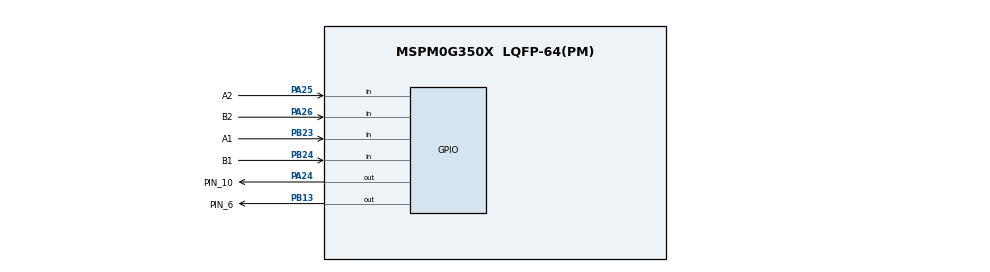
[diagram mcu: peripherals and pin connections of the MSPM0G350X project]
/**
 *
 * @cliArgs --device "MSPM0G350X" --part "Default" --package "LQFP-64(PM)" --product "mspm0_sdk@2.10.00.04"
 * @versions {"tool":"1.28.0+4712"}
 */

/**
 * Import the modules used in this configuration.
 */
const ADC12   = scripting.addModule("/ti/driverlib/ADC12", {}, false);
const ADC121  = ADC12.addInstance();
const GPIO    = scripting.addModule("/ti/driverlib/GPIO", {}, false);
const GPIO1   = GPIO.addInstance();
const GPIO2   = GPIO.addInstance();
const GPIO3   = GPIO.addInstance();
const GPIO4   = GPIO.addInstance();
const GPIO5   = GPIO.addInstance();
const GPIO6   = GPIO.addInstance();
const GPIO7   = GPIO.addInstance();
const GPIO8   = GPIO.addInstance();
const GPIO9   = GPIO.addInstance();
const GPIO10  = GPIO.addInstance();
const PWM     = scripting.addModule("/ti/driverlib/PWM", {}, false);
const PWM1    = PWM.addInstance();
const PWM2    = PWM.addInstance();
const SPI     = scripting.addModule("/ti/driverlib/SPI", {}, false);
const SPI1    = SPI.addInstance();
const SPI2    = SPI.addInstance();
const SYSCTL  = scripting.addModule("/ti/driverlib/SYSCTL");
const SYSTICK = scripting.addModule("/ti/driverlib/SYSTICK");
const TIMER   = scripting.addModule("/ti/driverlib/TIMER", {}, false);
const TIMER1  = TIMER.addInstance();
const TIMER2  = TIMER.addInstance();
const TIMER3  = TIMER.addInstance();
const UART    = scripting.addModule("/ti/driverlib/UART", {}, false);
const UART1   = UART.addInstance();
const UART2   = UART.addInstance();
const UART3   = UART.addInstance();
const UART4   = UART.addInstance();

/**
 * Write custom configuration values to the imported modules.
 */
const divider7       = system.clockTree["PLL_PDIV"];
divider7.divideValue = 2;

const divider9       = system.clockTree["UDIV"];
divider9.divideValue = 2;

const multiplier2         = system.clockTree["PLL_QDIV"];
multiplier2.multiplyValue = 5;

const mux8       = system.clockTree["HSCLKMUX"];
mux8.inputSelect = "HSCLKMUX_SYSPLL2X";

ADC121.$name                             = "ADCGraySensor";
ADC121.adcPin0Config.hideOutputInversion = scripting.forceWrite(false);
ADC121.adcPin0Config.$name               = "ti_driverlib_gpio_GPIOPinGeneric18";

const Board = scripting.addModule("/ti/driverlib/Board", {}, false);

GPIO1.$name                   = "GraySensor";
GPIO1.associatedPins.create(3);
GPIO1.associatedPins[0].$name = "PIN_0";
GPIO1.associatedPins[1].$name = "PIN_1";
GPIO1.associatedPins[2].$name = "PIN_2";

GPIO2.$name                   = "Key";
GPIO2.associatedPins.create(3);
GPIO2.associatedPins[0].$name = "PIN_3";
GPIO2.associatedPins[1].$name = "PIN_4";
GPIO2.associatedPins[2].$name = "PIN_5";

GPIO3.$name                         = "CS";
GPIO3.associatedPins[0].$name       = "PIN_6";
GPIO3.associatedPins[0].pin.$assign = "PB13";

GPIO4.$name                         = "Motor";
GPIO4.associatedPins.create(4);
GPIO4.associatedPins[0].$name       = "PIN_7";
GPIO4.associatedPins[1].$name       = "PIN_8";
GPIO4.associatedPins[2].$name       = "PIN_9";
GPIO4.associatedPins[3].$name       = "PIN_10";
GPIO4.associatedPins[3].pin.$assign = "PA24";

GPIO5.$name                               = "Encoder1";
GPIO5.associatedPins.create(2);
GPIO5.associatedPins[0].direction         = "INPUT";
GPIO5.associatedPins[0].$name             = "A1";
GPIO5.associatedPins[0].interruptEn       = true;
GPIO5.associatedPins[0].interruptPriority = "1";
GPIO5.associatedPins[0].polarity          = "RISE";
GPIO5.associatedPins[0].pin.$assign       = "PB23";
GPIO5.associatedPins[1].$name             = "B1";
GPIO5.associatedPins[1].direction         = "INPUT";
GPIO5.associatedPins[1].pin.$assign       = "PB24";

GPIO6.$name                   = "LED";
GPIO6.associatedPins[0].$name = "PIN_13";

GPIO7.$name                               = "Encoder2";
GPIO7.associatedPins.create(2);
GPIO7.associatedPins[0].$name             = "A2";
GPIO7.associatedPins[0].direction         = "INPUT";
GPIO7.associatedPins[0].interruptEn       = true;
GPIO7.associatedPins[0].interruptPriority = "1";
GPIO7.associatedPins[0].polarity          = "RISE";
GPIO7.associatedPins[0].pin.$assign       = "PA25";
GPIO7.associatedPins[1].$name             = "B2";
GPIO7.associatedPins[1].direction         = "INPUT";
GPIO7.associatedPins[1].pin.$assign       = "PA26";

GPIO8.$name                   = "DC";
GPIO8.associatedPins[0].$name = "PIN_11";

GPIO9.$name                   = "RES";
GPIO9.associatedPins[0].$name = "PIN_12";

GPIO10.$name                   = "BL";
GPIO10.associatedPins[0].$name = "PIN_14";

PWM1.$name               = "PWM_0";
PWM1.clockDivider        = 8;
PWM1.pwmMode             = "EDGE_ALIGN_UP";
PWM1.PWM_CHANNEL_0.$name = "ti_driverlib_pwm_PWMTimerCC0";
PWM1.PWM_CHANNEL_1.$name = "ti_driverlib_pwm_PWMTimerCC1";
PWM1.ccp0PinConfig.$name = "ti_driverlib_gpio_GPIOPinGeneric10";
PWM1.ccp1PinConfig.$name = "ti_driverlib_gpio_GPIOPinGeneric11";

PWM2.$name                              = "PWM_Buzzer";
PWM2.ccIndex                            = [0];
PWM2.clockDivider                       = 8;
PWM2.PWM_CHANNEL_0.$name                = "ti_driverlib_pwm_PWMTimerCC2";
PWM2.ccp0PinConfig.direction            = scripting.forceWrite("OUTPUT");
PWM2.ccp0PinConfig.hideOutputInversion  = scripting.forceWrite(false);
PWM2.ccp0PinConfig.onlyInternalResistor = scripting.forceWrite(false);
PWM2.ccp0PinConfig.passedPeripheralType = scripting.forceWrite("Digital");
PWM2.ccp0PinConfig.$name                = "ti_driverlib_gpio_GPIOPinGeneric19";

SPI1.$name               = "SPI_0";
SPI1.frameFormat         = "MOTO3";
SPI1.sclkPinConfig.$name = "ti_driverlib_gpio_GPIOPinGeneric14";
SPI1.mosiPinConfig.$name = "ti_driverlib_gpio_GPIOPinGeneric15";
SPI1.misoPinConfig.$name = "ti_driverlib_gpio_GPIOPinGeneric16";

SPI2.$name               = "SPI_1";
SPI2.sclkPinConfig.$name = "ti_driverlib_gpio_GPIOPinGeneric8";
SPI2.mosiPinConfig.$name = "ti_driverlib_gpio_GPIOPinGeneric9";
SPI2.misoPinConfig.$name = "ti_driverlib_gpio_GPIOPinGeneric12";
SPI2.cs0PinConfig.$name  = "ti_driverlib_gpio_GPIOPinGeneric13";

SYSCTL.forceDefaultClkConfig = true;
SYSCTL.clockTreeEn           = true;

SYSTICK.periodEnable      = true;
SYSTICK.interruptEnable   = true;
SYSTICK.systickEnable     = true;
SYSTICK.interruptPriority = "0";
SYSTICK.period            = 80000;

TIMER1.$name            = "TIMER_0";
TIMER1.timerMode        = "PERIODIC_UP";
TIMER1.timerPeriod      = "10 ms";
TIMER1.timerClkDiv      = 8;
TIMER1.interrupts       = ["ZERO"];
TIMER1.timerClkPrescale = 2;
TIMER1.timerStartTimer  = true;

TIMER2.$name            = "TIMER_1";
TIMER2.timerMode        = "PERIODIC";
TIMER2.timerPeriod      = "20 ms";
TIMER2.timerClkPrescale = 10;
TIMER2.timerClkDiv      = 8;

TIMER3.$name            = "TIMER_2";
TIMER3.timerMode        = "PERIODIC";
TIMER3.timerPeriod      = "50 ms";
TIMER3.timerClkDiv      = 8;
TIMER3.timerClkPrescale = 10;

UART1.$name             = "UART_0";
UART1.targetBaudRate    = 115200;
UART1.enabledInterrupts = ["RX"];
UART1.txPinConfig.$name = "ti_driverlib_gpio_GPIOPinGeneric0";
UART1.rxPinConfig.$name = "ti_driverlib_gpio_GPIOPinGeneric1";

UART2.$name             = "UART_1";
UART2.targetBaudRate    = 115200;
UART2.enabledInterrupts = ["RX"];
UART2.txPinConfig.$name = "ti_driverlib_gpio_GPIOPinGeneric2";
UART2.rxPinConfig.$name = "ti_driverlib_gpio_GPIOPinGeneric3";

UART3.$name             = "UART_2";
UART3.targetBaudRate    = 115200;
UART3.txPinConfig.$name = "ti_driverlib_gpio_GPIOPinGeneric4";
UART3.rxPinConfig.$name = "ti_driverlib_gpio_GPIOPinGeneric5";

UART4.$name             = "UART_3";
UART4.targetBaudRate    = 115200;
UART4.txPinConfig.$name = "ti_driverlib_gpio_GPIOPinGeneric6";
UART4.rxPinConfig.$name = "ti_driverlib_gpio_GPIOPinGeneric7";

/**
 * Pinmux solution for unlocked pins/peripherals. This ensures that minor changes to the automatic solver in a future
 * version of the tool will not impact the pinmux you originally saw.  These lines can be completely deleted in order to
 * re-solve from scratch.
 */
ADC121.peripheral.$suggestSolution            = "ADC1";
ADC121.peripheral.adcPin0.$suggestSolution    = "PA15";
Board.peripheral.$suggestSolution             = "DEBUGSS";
Board.peripheral.swclkPin.$suggestSolution    = "PA20";
Board.peripheral.swdioPin.$suggestSolution    = "PA19";
GPIO1.associatedPins[0].pin.$suggestSolution  = "PB19";
GPIO1.associatedPins[1].pin.$suggestSolution  = "PB20";
GPIO1.associatedPins[2].pin.$suggestSolution  = "PB21";
GPIO2.associatedPins[0].pin.$suggestSolution  = "PB22";
GPIO2.associatedPins[1].pin.$suggestSolution  = "PB25";
GPIO2.associatedPins[2].pin.$suggestSolution  = "PB26";
GPIO4.associatedPins[0].pin.$suggestSolution  = "PB27";
GPIO4.associatedPins[1].pin.$suggestSolution  = "PA28";
GPIO4.associatedPins[2].pin.$suggestSolution  = "PA30";
GPIO6.associatedPins[0].pin.$suggestSolution  = "PB14";
GPIO8.associatedPins[0].pin.$suggestSolution  = "PA12";
GPIO9.associatedPins[0].pin.$suggestSolution  = "PB17";
GPIO10.associatedPins[0].pin.$suggestSolution = "PB18";
PWM1.peripheral.$suggestSolution              = "TIMG7";
PWM1.peripheral.ccp0Pin.$suggestSolution      = "PA23";
PWM1.peripheral.ccp1Pin.$suggestSolution      = "PA27";
PWM2.peripheral.$suggestSolution              = "TIMG6";
PWM2.peripheral.ccp0Pin.$suggestSolution      = "PA29";
SPI1.peripheral.$suggestSolution              = "SPI1";
SPI1.peripheral.sclkPin.$suggestSolution      = "PB16";
SPI1.peripheral.mosiPin.$suggestSolution      = "PB15";
SPI1.peripheral.misoPin.$suggestSolution      = "PA16";
SPI2.peripheral.$suggestSolution              = "SPI0";
SPI2.peripheral.sclkPin.$suggestSolution      = "PA11";
SPI2.peripheral.mosiPin.$suggestSolution      = "PA5";
SPI2.peripheral.misoPin.$suggestSolution      = "PA10";
SPI2.peripheral.cs0Pin.$suggestSolution       = "PA2";
TIMER1.peripheral.$suggestSolution            = "TIMG0";
TIMER2.peripheral.$suggestSolution            = "TIMA1";
TIMER3.peripheral.$suggestSolution            = "TIMA0";
UART1.peripheral.$suggestSolution             = "UART3";
UART1.peripheral.rxPin.$suggestSolution       = "PA13";
UART1.peripheral.txPin.$suggestSolution       = "PA14";
UART2.peripheral.$suggestSolution             = "UART2";
UART2.peripheral.rxPin.$suggestSolution       = "PA22";
UART2.peripheral.txPin.$suggestSolution       = "PA21";
UART3.peripheral.$suggestSolution             = "UART1";
UART3.peripheral.rxPin.$suggestSolution       = "PA18";
UART3.peripheral.txPin.$suggestSolution       = "PA17";
UART4.peripheral.$suggestSolution             = "UART0";
UART4.peripheral.rxPin.$suggestSolution       = "PA1";
UART4.peripheral.txPin.$suggestSolution       = "PA0";
